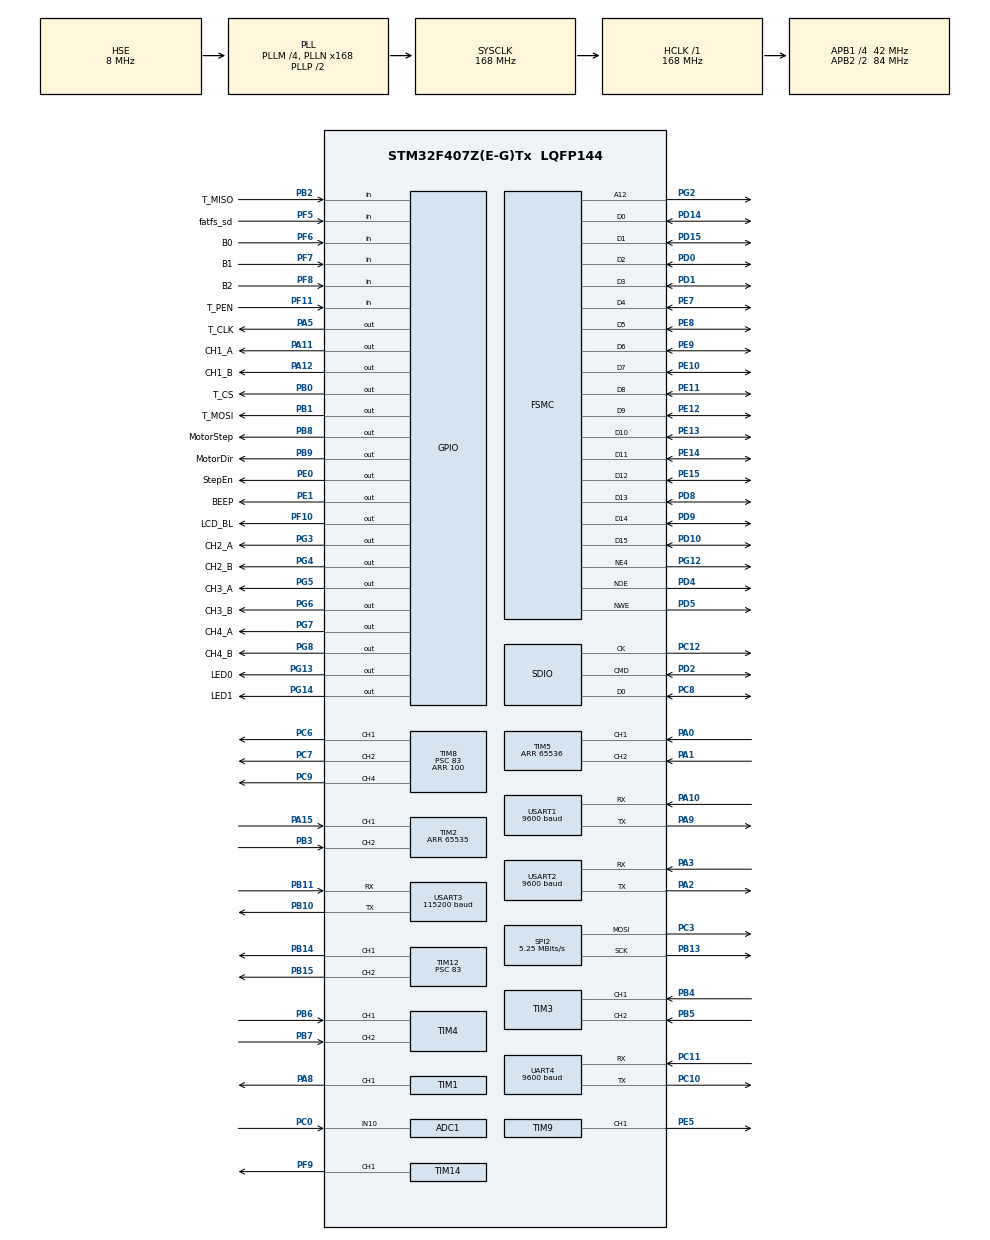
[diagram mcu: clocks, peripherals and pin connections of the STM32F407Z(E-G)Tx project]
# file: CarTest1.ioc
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ADC1.Channel-0\#ChannelRegularConversion=ADC_CHANNEL_10
ADC1.NbrOfConversionFlag=1
ADC1.Rank-0\#ChannelRegularConversion=1
ADC1.SamplingTime-0\#ChannelRegularConversion=ADC_SAMPLETIME_3CYCLES
ADC1.master=1
Dma.Request0=SDIO
Dma.Request1=SPI2_TX
Dma.SDIO.0.Direction=DMA_PERIPH_TO_MEMORY
Dma.SDIO.0.FIFOMode=DMA_FIFOMODE_ENABLE
Dma.SDIO.0.FIFOThreshold=DMA_FIFO_THRESHOLD_FULL
Dma.SDIO.0.Instance=DMA2_Stream3
Dma.SDIO.0.MemBurst=DMA_MBURST_INC4
Dma.SDIO.0.MemDataAlignment=DMA_MDATAALIGN_WORD
Dma.SDIO.0.MemInc=DMA_MINC_ENABLE
Dma.SDIO.0.Mode=DMA_PFCTRL
Dma.SDIO.0.PeriphBurst=DMA_PBURST_INC4
Dma.SDIO.0.PeriphDataAlignment=DMA_PDATAALIGN_WORD
Dma.SDIO.0.PeriphInc=DMA_PINC_DISABLE
Dma.SDIO.0.Priority=DMA_PRIORITY_LOW
Dma.SPI2_TX.1.Direction=DMA_MEMORY_TO_PERIPH
Dma.SPI2_TX.1.FIFOMode=DMA_FIFOMODE_DISABLE
Dma.SPI2_TX.1.Instance=DMA1_Stream4
Dma.SPI2_TX.1.MemDataAlignment=DMA_MDATAALIGN_BYTE
Dma.SPI2_TX.1.MemInc=DMA_MINC_ENABLE
Dma.SPI2_TX.1.Mode=DMA_NORMAL
Dma.SPI2_TX.1.PeriphDataAlignment=DMA_PDATAALIGN_BYTE
Dma.SPI2_TX.1.PeriphInc=DMA_PINC_DISABLE
Dma.SPI2_TX.1.Priority=DMA_PRIORITY_LOW
FATFS.BSP.number=1
FATFS._CODE_PAGE=936
FATFS._USE_LFN=2
FATFS0.BSP.STBoard=false
FATFS0.BSP.api=Unknown
FATFS0.BSP.instance=PF5
FATFS0.BSP.ip=GPIO
FATFS0.BSP.mode=Input
FATFS0.BSP.name=Detect_SDIO
FATFS0.BSP.solution=PF5
FREERTOS.Tasks01=defaultTask,0,128,StartDefaultTask,Default,NULL,Dynamic,NULL,NULL
FREERTOS.configTOTAL_HEAP_SIZE=25360
IWDG.Prescaler=IWDG_PRESCALER_32
IWDG.Reload=100
Mcu.Family=STM32F4
Mcu.Name=STM32F407Z(E-G)Tx
Mcu.Package=LQFP144
NVIC.DMA1_Stream4_IRQn=true\:5\:0\:false\:false\:true\:true\:false\:true\:true
NVIC.DMA2_Stream3_IRQn=true\:5\:0\:false\:false\:true\:true\:false\:true\:true
NVIC.PriorityGroup=NVIC_PRIORITYGROUP_4
NVIC.TIM1_UP_TIM10_IRQn=true\:5\:0\:true\:false\:true\:true\:true\:true\:true
NVIC.TIM8_TRG_COM_TIM14_IRQn=true\:14\:0\:true\:false\:true\:true\:true\:true\:true
NVIC.TIM8_UP_TIM13_IRQn=true\:15\:0\:false\:false\:true\:false\:false\:true\:true
NVIC.TimeBase=TIM8_UP_TIM13_IRQn
NVIC.TimeBaseIP=TIM13
NVIC.UART4_IRQn=true\:5\:0\:false\:false\:true\:true\:true\:true\:true
NVIC.USART1_IRQn=true\:15\:0\:true\:false\:true\:true\:true\:true\:true
NVIC.USART2_IRQn=true\:10\:0\:true\:false\:true\:true\:true\:true\:true
NVIC.USART3_IRQn=true\:13\:0\:true\:false\:true\:true\:true\:true\:true
PA0-WKUP.Signal=S_TIM5_CH1
PA1.Signal=S_TIM5_CH2
PA10.Mode=Asynchronous
PA10.Signal=USART1_RX
PA11.GPIO_Label=CH1_A
PA11.GPIO_Speed=GPIO_SPEED_FREQ_HIGH
PA11.Signal=GPIO_Output
PA12.GPIO_Label=CH1_B
PA12.Signal=GPIO_Output
PA13.Mode=Serial_Wire
PA13.Signal=SYS_JTMS-SWDIO
PA14.Mode=Serial_Wire
PA14.Signal=SYS_JTCK-SWCLK
PA15.Signal=S_TIM2_CH1_ETR
PA2.Mode=Asynchronous
PA2.Signal=USART2_TX
PA3.Mode=Asynchronous
PA3.Signal=USART2_RX
PA5.GPIO_Label=T_CLK
PA5.GPIO_Speed=GPIO_SPEED_FREQ_HIGH
PA5.Signal=GPIO_Output
PA8.Signal=S_TIM1_CH1
PA9.Mode=Asynchronous
PA9.Signal=USART1_TX
PB0.GPIO_Label=T_CS
PB0.GPIO_Speed=GPIO_SPEED_FREQ_HIGH
PB0.Signal=GPIO_Output
PB1.GPIO_Label=T_MOSI
PB1.GPIO_Speed=GPIO_SPEED_FREQ_HIGH
PB1.Signal=GPIO_Output
PB10.Mode=Asynchronous
PB10.Signal=USART3_TX
PB11.Mode=Asynchronous
PB11.Signal=USART3_RX
PB13.Mode=TX_Only_Simplex_Unidirect_Master
PB13.Signal=SPI2_SCK
PB14.Signal=S_TIM12_CH1
PB15.Signal=S_TIM12_CH2
PB2.GPIO_Label=T_MISO
PB2.Signal=GPIO_Input
PB3.Signal=S_TIM2_CH2
PB4.Signal=S_TIM3_CH1
PB5.Signal=S_TIM3_CH2
PB6.Signal=S_TIM4_CH1
PB7.Signal=S_TIM4_CH2
PB8.GPIO_Label=MotorStep
PB8.GPIO_Speed=GPIO_SPEED_FREQ_VERY_HIGH
PB8.Signal=GPIO_Output
PB9.GPIO_Label=MotorDir
PB9.Signal=GPIO_Output
PC0.Signal=ADCx_IN10
PC10.Mode=Asynchronous
PC10.Signal=UART4_TX
PC11.Mode=Asynchronous
PC11.Signal=UART4_RX
PC12.Mode=SD_1_bit
PC12.Signal=SDIO_CK
PC14-OSC32_IN.Mode=LSE-External-Oscillator
PC14-OSC32_IN.Signal=RCC_OSC32_IN
PC15-OSC32_OUT.Mode=LSE-External-Oscillator
PC15-OSC32_OUT.Signal=RCC_OSC32_OUT
PC3.Mode=TX_Only_Simplex_Unidirect_Master
PC3.Signal=SPI2_MOSI
PC6.Signal=S_TIM8_CH1
PC7.Signal=S_TIM8_CH2
PC8.Mode=SD_1_bit
PC8.Signal=SDIO_D0
PC9.Signal=S_TIM8_CH4
PD0.Signal=FSMC_D2_DA2
PD1.Signal=FSMC_D3_DA3
PD10.Signal=FSMC_D15_DA15
PD14.Signal=FSMC_D0_DA0
PD15.Signal=FSMC_D1_DA1
PD2.Mode=SD_1_bit
PD2.Signal=SDIO_CMD
PD4.Signal=FSMC_NOE
PD5.Signal=FSMC_NWE
PD8.Signal=FSMC_D13_DA13
PD9.Signal=FSMC_D14_DA14
PE0.GPIO_Label=StepEn
PE0.Signal=GPIO_Output
PE1.GPIO_Label=BEEP
PE1.Signal=GPIO_Output
PE10.Signal=FSMC_D7_DA7
PE11.Signal=FSMC_D8_DA8
PE12.Signal=FSMC_D9_DA9
PE13.Signal=FSMC_D10_DA10
PE14.Signal=FSMC_D11_DA11
PE15.Signal=FSMC_D12_DA12
PE5.Signal=S_TIM9_CH1
PE7.Signal=FSMC_D4_DA4
PE8.Signal=FSMC_D5_DA5
PE9.Signal=FSMC_D6_DA6
PF10.GPIO_Label=LCD_BL
PF10.PinState=GPIO_PIN_SET
PF10.Signal=GPIO_Output
PF11.GPIO_Label=T_PEN
PF11.Signal=GPIO_Input
PF5.GPIO_Label=fatfs_sd
PF5.Signal=GPIO_Input
PF6.GPIO_Label=B0
PF6.Signal=GPIO_Input
PF7.GPIO_Label=B1
PF7.Signal=GPIO_Input
PF8.GPIO_Label=B2
PF8.Signal=GPIO_Input
PF9.Signal=S_TIM14_CH1
PG12.Mode=NorPsramChipSelect4_1
PG12.Signal=FSMC_NE4
PG13.GPIO_Label=LED0
PG13.PinState=GPIO_PIN_SET
PG13.Signal=GPIO_Output
PG14.GPIO_Label=LED1
PG14.PinState=GPIO_PIN_SET
PG14.Signal=GPIO_Output
PG2.Signal=FSMC_A12
PG3.GPIO_Label=CH2_A
PG3.GPIO_Speed=GPIO_SPEED_FREQ_HIGH
PG3.Signal=GPIO_Output
PG4.GPIO_Label=CH2_B
PG4.GPIO_Speed=GPIO_SPEED_FREQ_HIGH
PG4.Signal=GPIO_Output
PG5.GPIO_Label=CH3_A
PG5.GPIO_Speed=GPIO_SPEED_FREQ_HIGH
PG5.Signal=GPIO_Output
PG6.GPIO_Label=CH3_B
PG6.GPIO_Speed=GPIO_SPEED_FREQ_HIGH
PG6.Signal=GPIO_Output
PG7.GPIO_Label=CH4_A
PG7.GPIO_Speed=GPIO_SPEED_FREQ_HIGH
PG7.Signal=GPIO_Output
PG8.GPIO_Label=CH4_B
PG8.GPIO_Speed=GPIO_SPEED_FREQ_HIGH
PG8.Signal=GPIO_Output
PH0-OSC_IN.Mode=HSE-External-Oscillator
PH0-OSC_IN.Signal=RCC_OSC_IN
PH1-OSC_OUT.Mode=HSE-External-Oscillator
PH1-OSC_OUT.Signal=RCC_OSC_OUT
ProjectManager.HeapSize=0x7000
ProjectManager.StackSize=0x1500
ProjectManager.TargetToolchain=MDK-ARM V5.32
RCC.48MHZClocksFreq_Value=48000000
RCC.AHBFreq_Value=168000000
RCC.APB1CLKDivider=RCC_HCLK_DIV4
RCC.APB1Freq_Value=42000000
RCC.APB1TimFreq_Value=84000000
RCC.APB2CLKDivider=RCC_HCLK_DIV2
RCC.APB2Freq_Value=84000000
RCC.APB2TimFreq_Value=168000000
RCC.CortexFreq_Value=168000000
RCC.FLatency=FLASH_LATENCY_5
RCC.HCLKFreq_Value=168000000
RCC.HSE_VALUE=8000000
RCC.HSI_VALUE=16000000
RCC.PLLM=4
RCC.PLLN=168
RCC.PLLQ=7
RCC.PLLSourceVirtual=RCC_PLLSOURCE_HSE
RCC.SYSCLKFreq_VALUE=168000000
RCC.SYSCLKSource=RCC_SYSCLKSOURCE_PLLCLK
RCC.VCOOutputFreq_Value=336000000
SH.ADCx_IN10.0=ADC1_IN10,IN10
SH.FSMC_A12.0=FSMC_A12,A12_1
SH.FSMC_D0_DA0.0=FSMC_D0,16b-d1
SH.FSMC_D10_DA10.0=FSMC_D10,16b-d1
SH.FSMC_D11_DA11.0=FSMC_D11,16b-d1
SH.FSMC_D12_DA12.0=FSMC_D12,16b-d1
SH.FSMC_D13_DA13.0=FSMC_D13,16b-d1
SH.FSMC_D14_DA14.0=FSMC_D14,16b-d1
SH.FSMC_D15_DA15.0=FSMC_D15,16b-d1
SH.FSMC_D1_DA1.0=FSMC_D1,16b-d1
SH.FSMC_D2_DA2.0=FSMC_D2,16b-d1
SH.FSMC_D3_DA3.0=FSMC_D3,16b-d1
SH.FSMC_D4_DA4.0=FSMC_D4,16b-d1
SH.FSMC_D5_DA5.0=FSMC_D5,16b-d1
SH.FSMC_D6_DA6.0=FSMC_D6,16b-d1
SH.FSMC_D7_DA7.0=FSMC_D7,16b-d1
SH.FSMC_D8_DA8.0=FSMC_D8,16b-d1
SH.FSMC_D9_DA9.0=FSMC_D9,16b-d1
SH.FSMC_NOE.0=FSMC_NOE,Lcd1
SH.FSMC_NWE.0=FSMC_NWE,Lcd1
SH.S_TIM12_CH1.0=TIM12_CH1,PWM Generation1 CH1
SH.S_TIM12_CH2.0=TIM12_CH2,PWM Generation2 CH2
SH.S_TIM14_CH1.0=TIM14_CH1,PWM Generation1 CH1
SH.S_TIM1_CH1.0=TIM1_CH1,PWM Generation1 CH1
SH.S_TIM2_CH1_ETR.0=TIM2_CH1,Encoder_Interface
SH.S_TIM2_CH2.0=TIM2_CH2,Encoder_Interface
SH.S_TIM3_CH1.0=TIM3_CH1,Encoder_Interface
SH.S_TIM3_CH2.0=TIM3_CH2,Encoder_Interface
SH.S_TIM4_CH1.0=TIM4_CH1,Encoder_Interface
SH.S_TIM4_CH2.0=TIM4_CH2,Encoder_Interface
SH.S_TIM5_CH1.0=TIM5_CH1,Encoder_Interface
SH.S_TIM5_CH2.0=TIM5_CH2,Encoder_Interface
SH.S_TIM8_CH1.0=TIM8_CH1,PWM Generation1 CH1
SH.S_TIM8_CH2.0=TIM8_CH2,PWM Generation2 CH2
SH.S_TIM8_CH4.0=TIM8_CH4,PWM Generation4 CH4
SH.S_TIM9_CH1.0=TIM9_CH1,PWM Generation1 CH1
SPI2.BaudRatePrescaler=SPI_BAUDRATEPRESCALER_8
SPI2.CalculateBaudRate=5.25 MBits/s
SPI2.Direction=SPI_DIRECTION_2LINES
SPI2.Mode=SPI_MODE_MASTER
SPI2.VirtualType=VM_MASTER
TIM1.Channel-PWM\ Generation1\ CH1=TIM_CHANNEL_1
TIM1.Period=100
TIM1.Prescaler=167
TIM10.Period=100
TIM10.Prescaler=167
TIM12.Channel-PWM\ Generation1\ CH1=TIM_CHANNEL_1
TIM12.Channel-PWM\ Generation2\ CH2=TIM_CHANNEL_2
TIM12.Period=20000
TIM12.Prescaler=83
TIM14.Channel=TIM_CHANNEL_1
TIM14.Period=20000
TIM14.Prescaler=83
TIM2.EncoderMode=TIM_ENCODERMODE_TI12
TIM2.IC1Filter=15
TIM2.IC2Filter=15
TIM2.Period=65535
TIM3.EncoderMode=TIM_ENCODERMODE_TI12
TIM3.IC1Filter=15
TIM3.IC2Filter=15
TIM4.EncoderMode=TIM_ENCODERMODE_TI12
TIM4.IC1Filter=15
TIM4.IC2Filter=15
TIM5.EncoderMode=TIM_ENCODERMODE_TI12
TIM5.IC1Filter=15
TIM5.IC2Filter=15
TIM5.Period=65536
TIM8.Channel-PWM\ Generation1\ CH1=TIM_CHANNEL_1
TIM8.Channel-PWM\ Generation2\ CH2=TIM_CHANNEL_2
TIM8.Channel-PWM\ Generation4\ CH4=TIM_CHANNEL_4
TIM8.Period=100
TIM8.Prescaler=83
TIM9.Channel-PWM\ Generation1\ CH1=TIM_CHANNEL_1
TIM9.Period=20000
TIM9.Prescaler=167
UART4.BaudRate=9600
UART4.VirtualMode=Asynchronous
USART1.BaudRate=9600
USART1.Mode=MODE_TX_RX
USART1.OverSampling=UART_OVERSAMPLING_16
USART1.Parity=PARITY_NONE
USART1.StopBits=STOPBITS_1
USART1.VirtualMode=VM_ASYNC
USART1.WordLength=WORDLENGTH_8B
USART2.BaudRate=9600
USART2.VirtualMode=VM_ASYNC
USART3.BaudRate=115200
USART3.VirtualMode=VM_ASYNC
VP_FATFS_VS_SDIO.Mode=SDIO
VP_FREERTOS_VS_CMSIS_V1.Mode=CMSIS_V1
VP_IWDG_VS_IWDG.Mode=IWDG_Activate
VP_SYS_VS_tim13.Mode=TIM13
VP_TIM10_VS_ClockSourceINT.Mode=Enable_Timer
VP_TIM14_VS_ClockSourceINT.Mode=Enable_Timer
board=custom

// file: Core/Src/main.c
/* USER CODE BEGIN Header */
/**
  ******************************************************************************
  * @file           : main.c
  * @brief          : Main program body
  ******************************************************************************
  * @attention
  *
  * Copyright (c) 2023 STMicroelectronics.
  * All rights reserved.
  *
  * This software is licensed under terms that can be found in the LICENSE file
  * in the root directory of this software component.
  * If no LICENSE file comes with this software, it is provided AS-IS.
  *
  ******************************************************************************
  */
/* USER CODE END Header */
#include "main.h"
#include "cmsis_os.h"
#include "adc.h"
#include "dma.h"
#include "fatfs.h"
#include "iwdg.h"
#include "sdio.h"
#include "spi.h"
#include "tim.h"
#include "usart.h"
#include "gpio.h"
#include "fsmc.h"

/* USER CODE BEGIN Includes */
#include "my_sys.h"
#include "lvgl.h"
#include "my_lib/step_motor.h"
/* USER CODE END Includes */

void SystemClock_Config(void);
void MX_FREERTOS_Init(void);

int main(void)
{

  /* MCU Configuration--------------------------------------------------------*/

  /* Reset of all peripherals, Initializes the Flash interface and the Systick. */
  HAL_Init();

  /* Configure the system clock */
  SystemClock_Config();

  /* Initialize all configured peripherals */
  MX_GPIO_Init();
  MX_DMA_Init();
  MX_USART1_UART_Init();
  MX_FSMC_Init();
  MX_USART2_UART_Init();
  MX_TIM2_Init();
  MX_TIM3_Init();
  MX_TIM4_Init();
  MX_TIM5_Init();
  MX_TIM8_Init();
  MX_USART3_UART_Init();
  MX_SDIO_SD_Init();
  MX_FATFS_Init();
  MX_TIM1_Init();
  MX_SPI2_Init();
  MX_TIM10_Init();
  MX_TIM12_Init();
  MX_TIM14_Init();
  MX_UART4_Init();
  MX_TIM9_Init();
  // MX_IWDG_Init();
  MX_ADC1_Init();
  /* USER CODE BEGIN 2 */

  // MainInit();

  /* USER CODE END 2 */

  /* Call init function for freertos objects (in freertos.c) */
  MX_FREERTOS_Init();

  /* Start scheduler */
  osKernelStart();
  /* We should never get here as control is now taken by the scheduler */
  /* Infinite loop */
  while (1)
  {

    /* USER CODE BEGIN 3 */
    // MainLoop();
  }
  /* USER CODE END 3 */
}

void SystemClock_Config(void)
{
  RCC_OscInitTypeDef RCC_OscInitStruct = {0};
  RCC_ClkInitTypeDef RCC_ClkInitStruct = {0};

  /** Configure the main internal regulator output voltage
  */
  __HAL_RCC_PWR_CLK_ENABLE();
  __HAL_PWR_VOLTAGESCALING_CONFIG(PWR_REGULATOR_VOLTAGE_SCALE1);

  /** Initializes the RCC Oscillators according to the specified parameters
  * in the RCC_OscInitTypeDef structure.
  */
  RCC_OscInitStruct.OscillatorType = RCC_OSCILLATORTYPE_LSI|RCC_OSCILLATORTYPE_HSE;
  RCC_OscInitStruct.HSEState = RCC_HSE_ON;
  RCC_OscInitStruct.LSIState = RCC_LSI_ON;
  RCC_OscInitStruct.PLL.PLLState = RCC_PLL_ON;
  RCC_OscInitStruct.PLL.PLLSource = RCC_PLLSOURCE_HSE;
  RCC_OscInitStruct.PLL.PLLM = 4;
  RCC_OscInitStruct.PLL.PLLN = 168;
  RCC_OscInitStruct.PLL.PLLP = RCC_PLLP_DIV2;
  RCC_OscInitStruct.PLL.PLLQ = 7;
  if (HAL_RCC_OscConfig(&RCC_OscInitStruct) != HAL_OK)
  {
    Error_Handler();
  }

  /** Initializes the CPU, AHB and APB buses clocks
  */
  RCC_ClkInitStruct.ClockType = RCC_CLOCKTYPE_HCLK|RCC_CLOCKTYPE_SYSCLK
                              |RCC_CLOCKTYPE_PCLK1|RCC_CLOCKTYPE_PCLK2;
  RCC_ClkInitStruct.SYSCLKSource = RCC_SYSCLKSOURCE_PLLCLK;
  RCC_ClkInitStruct.AHBCLKDivider = RCC_SYSCLK_DIV1;
  RCC_ClkInitStruct.APB1CLKDivider = RCC_HCLK_DIV4;
  RCC_ClkInitStruct.APB2CLKDivider = RCC_HCLK_DIV2;

  if (HAL_RCC_ClockConfig(&RCC_ClkInitStruct, FLASH_LATENCY_5) != HAL_OK)
  {
    Error_Handler();
  }
}

void HAL_TIM_PeriodElapsedCallback(TIM_HandleTypeDef *htim)
{
  /* USER CODE BEGIN Callback 0 */
  if(htim->Instance == TIM13){
    AddSysTick(1);
    lv_tick_inc(1);
  }
  if(htim->Instance == STEP_MOTOR_TIM.Instance){
    StepMotorTIM_Ctrl();
  }

  /* USER CODE END Callback 0 */
  if (htim->Instance == TIM13) {
    HAL_IncTick();
  }
}

void Error_Handler(void)
{
  __disable_irq();
  while (1)
  {
  }
}

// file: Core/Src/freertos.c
/* USER CODE BEGIN Header */
/**
  ******************************************************************************
  * File Name          : freertos.c
  * Description        : Code for freertos applications
  ******************************************************************************
  * @attention
  *
  * Copyright (c) 2023 STMicroelectronics.
  * All rights reserved.
  *
  * This software is licensed under terms that can be found in the LICENSE file
  * in the root directory of this software component.
  * If no LICENSE file comes with this software, it is provided AS-IS.
  *
  ******************************************************************************
  */
/* USER CODE END Header */

#include "FreeRTOS.h"
#include "task.h"
#include "main.h"
#include "cmsis_os.h"

/* USER CODE BEGIN Includes */
#include "my_sys.h"
/* USER CODE END Includes */

osThreadId defaultTaskHandle;

void StartDefaultTask(void const * argument);

void MX_FREERTOS_Init(void); /* (MISRA C 2004 rule 8.1) */

/* GetIdleTaskMemory prototype (linked to static allocation support) */
void vApplicationGetIdleTaskMemory( StaticTask_t **ppxIdleTaskTCBBuffer, StackType_t **ppxIdleTaskStackBuffer, uint32_t *pulIdleTaskStackSize );

/* USER CODE BEGIN GET_IDLE_TASK_MEMORY */
static StaticTask_t xIdleTaskTCBBuffer;
static StackType_t xIdleStack[configMINIMAL_STACK_SIZE];

void vApplicationGetIdleTaskMemory( StaticTask_t **ppxIdleTaskTCBBuffer, StackType_t **ppxIdleTaskStackBuffer, uint32_t *pulIdleTaskStackSize )
{
  *ppxIdleTaskTCBBuffer = &xIdleTaskTCBBuffer;
  *ppxIdleTaskStackBuffer = &xIdleStack[0];
  *pulIdleTaskStackSize = configMINIMAL_STACK_SIZE;
  /* place for user code */
}
/* USER CODE END GET_IDLE_TASK_MEMORY */

void MX_FREERTOS_Init(void) {
  /* USER CODE BEGIN Init */
  MyRTOS_Init();
  /* USER CODE END Init */

  /* Create the thread(s) */
  /* definition and creation of defaultTask */
  osThreadDef(defaultTask, StartDefaultTask, osPriorityNormal, 0, 128);
  defaultTaskHandle = osThreadCreate(osThread(defaultTask), NULL);

}

void StartDefaultTask(void const * argument)
{
  for(;;)
  {
    osDelay(1);
  }
}
